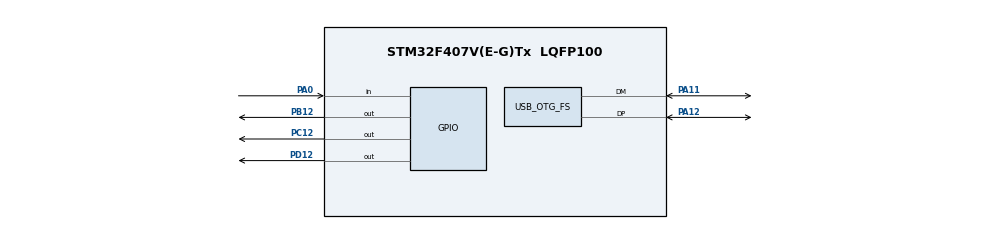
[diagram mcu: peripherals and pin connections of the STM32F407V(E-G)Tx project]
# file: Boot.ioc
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Mcu.Family=STM32F4
Mcu.Name=STM32F407V(E-G)Tx
Mcu.Package=LQFP100
NVIC.PriorityGroup=NVIC_PRIORITYGROUP_4
PA0-WKUP.Signal=GPIO_Input
PA11.Mode=Device_Only
PA11.Signal=USB_OTG_FS_DM
PA12.Mode=Device_Only
PA12.Signal=USB_OTG_FS_DP
PB12.Signal=GPIO_Output
PC12.Signal=GPIO_Output
PD12.Signal=GPIO_Output
PH0-OSC_IN.Mode=HSE-External-Oscillator
PH0-OSC_IN.Signal=RCC_OSC_IN
PH1-OSC_OUT.Mode=HSE-External-Oscillator
PH1-OSC_OUT.Signal=RCC_OSC_OUT
ProjectManager.HeapSize=0x200
ProjectManager.StackSize=0x400
ProjectManager.TargetToolchain=STM32CubeIDE
RCC.48MHZClocksFreq_Value=48000000
RCC.AHBFreq_Value=168000000
RCC.APB1CLKDivider=RCC_HCLK_DIV4
RCC.APB1Freq_Value=42000000
RCC.APB1TimFreq_Value=84000000
RCC.APB2CLKDivider=RCC_HCLK_DIV2
RCC.APB2Freq_Value=84000000
RCC.APB2TimFreq_Value=168000000
RCC.CortexFreq_Value=168000000
RCC.HCLKFreq_Value=168000000
RCC.HSE_VALUE=8000000
RCC.HSI_VALUE=16000000
RCC.LSE_VALUE=32768
RCC.PLLM=4
RCC.PLLN=168
RCC.PLLQ=7
RCC.SYSCLKFreq_VALUE=168000000
RCC.SYSCLKSource=RCC_SYSCLKSOURCE_PLLCLK
RCC.VCOOutputFreq_Value=336000000
USB_OTG_FS.Sof_enable=ENABLE
USB_OTG_FS.VirtualMode=Device_Only
board=custom

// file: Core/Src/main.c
/* USER CODE BEGIN Header */
/**
  ******************************************************************************
  * @file           : main.c
  * @brief          : Main program body
  ******************************************************************************
  * @attention
  *
  * Copyright (c) 2024 STMicroelectronics.
  * All rights reserved.
  *
  * This software is licensed under terms that can be found in the LICENSE file
  * in the root directory of this software component.
  * If no LICENSE file comes with this software, it is provided AS-IS.
  *
  ******************************************************************************
  */
/* USER CODE END Header */
#include "main.h"

/* USER CODE BEGIN Includes */
#include "app.h"
/* USER CODE END Includes */

PCD_HandleTypeDef hpcd_USB_OTG_FS;

void SystemClock_Config(void);
static void MX_GPIO_Init(void);

int main(void)
{

  /* MCU Configuration--------------------------------------------------------*/

  /* Reset of all peripherals, Initializes the Flash interface and the Systick. */
  HAL_Init();

  /* Configure the system clock */
  SystemClock_Config();

  /* Initialize all configured peripherals */
  MX_GPIO_Init();
  /* USER CODE BEGIN 2 */
  AppInit();
  /* USER CODE END 2 */

  /* Infinite loop */
  /* USER CODE BEGIN WHILE */
  while (1)
  {

	  AppTask();

    /* USER CODE END WHILE */

  }
}

void SystemClock_Config(void)
{
  LL_FLASH_SetLatency(LL_FLASH_LATENCY_5);
  while(LL_FLASH_GetLatency()!= LL_FLASH_LATENCY_5)
  {
  }
  LL_PWR_SetRegulVoltageScaling(LL_PWR_REGU_VOLTAGE_SCALE1);
  while (LL_PWR_IsActiveFlag_VOS() == 0)
  {
  }
  LL_RCC_HSE_Enable();

   /* Wait till HSE is ready */
  while(LL_RCC_HSE_IsReady() != 1)
  {

  }
  LL_RCC_PLL_ConfigDomain_SYS(LL_RCC_PLLSOURCE_HSE, LL_RCC_PLLM_DIV_4, 168, LL_RCC_PLLP_DIV_2);
  LL_RCC_PLL_ConfigDomain_48M(LL_RCC_PLLSOURCE_HSE, LL_RCC_PLLM_DIV_4, 168, LL_RCC_PLLQ_DIV_7);
  LL_RCC_PLL_Enable();

   /* Wait till PLL is ready */
  while(LL_RCC_PLL_IsReady() != 1)
  {

  }
  LL_RCC_SetAHBPrescaler(LL_RCC_SYSCLK_DIV_1);
  LL_RCC_SetAPB1Prescaler(LL_RCC_APB1_DIV_4);
  LL_RCC_SetAPB2Prescaler(LL_RCC_APB2_DIV_2);
  LL_RCC_SetSysClkSource(LL_RCC_SYS_CLKSOURCE_PLL);

   /* Wait till System clock is ready */
  while(LL_RCC_GetSysClkSource() != LL_RCC_SYS_CLKSOURCE_STATUS_PLL)
  {

  }
  LL_SetSystemCoreClock(168000000);

   /* Update the time base */
  if (HAL_InitTick (TICK_INT_PRIORITY) != HAL_OK)
  {
    Error_Handler();
  }
}

void MX_USB_OTG_FS_PCD_Init(void)
{

  hpcd_USB_OTG_FS.Instance = USB_OTG_FS;
  hpcd_USB_OTG_FS.Init.dev_endpoints = 4;
  hpcd_USB_OTG_FS.Init.speed = PCD_SPEED_FULL;
  hpcd_USB_OTG_FS.Init.dma_enable = DISABLE;
  hpcd_USB_OTG_FS.Init.phy_itface = PCD_PHY_EMBEDDED;
  hpcd_USB_OTG_FS.Init.Sof_enable = ENABLE;
  hpcd_USB_OTG_FS.Init.low_power_enable = DISABLE;
  hpcd_USB_OTG_FS.Init.lpm_enable = DISABLE;
  hpcd_USB_OTG_FS.Init.vbus_sensing_enable = DISABLE;
  hpcd_USB_OTG_FS.Init.use_dedicated_ep1 = DISABLE;
  if (HAL_PCD_Init(&hpcd_USB_OTG_FS) != HAL_OK)
  {
    Error_Handler();
  }

}

static void MX_GPIO_Init(void)
{
  LL_GPIO_InitTypeDef GPIO_InitStruct = {0};

  /* GPIO Ports Clock Enable */
  LL_AHB1_GRP1_EnableClock(LL_AHB1_GRP1_PERIPH_GPIOH);
  LL_AHB1_GRP1_EnableClock(LL_AHB1_GRP1_PERIPH_GPIOA);
  LL_AHB1_GRP1_EnableClock(LL_AHB1_GRP1_PERIPH_GPIOB);
  LL_AHB1_GRP1_EnableClock(LL_AHB1_GRP1_PERIPH_GPIOD);
  LL_AHB1_GRP1_EnableClock(LL_AHB1_GRP1_PERIPH_GPIOC);

  /**/
  LL_GPIO_ResetOutputPin(GPIOB, LL_GPIO_PIN_12);

  /**/
  LL_GPIO_ResetOutputPin(GPIOD, LL_GPIO_PIN_12);

  /**/
  LL_GPIO_ResetOutputPin(GPIOC, LL_GPIO_PIN_12);

  /**/
  GPIO_InitStruct.Pin = LL_GPIO_PIN_0;
  GPIO_InitStruct.Mode = LL_GPIO_MODE_INPUT;
  GPIO_InitStruct.Pull = LL_GPIO_PULL_NO;
  LL_GPIO_Init(GPIOA, &GPIO_InitStruct);

  /**/
  GPIO_InitStruct.Pin = LL_GPIO_PIN_12;
  GPIO_InitStruct.Mode = LL_GPIO_MODE_OUTPUT;
  GPIO_InitStruct.Speed = LL_GPIO_SPEED_FREQ_LOW;
  GPIO_InitStruct.OutputType = LL_GPIO_OUTPUT_PUSHPULL;
  GPIO_InitStruct.Pull = LL_GPIO_PULL_NO;
  LL_GPIO_Init(GPIOB, &GPIO_InitStruct);

  /**/
  GPIO_InitStruct.Pin = LL_GPIO_PIN_12;
  GPIO_InitStruct.Mode = LL_GPIO_MODE_OUTPUT;
  GPIO_InitStruct.Speed = LL_GPIO_SPEED_FREQ_LOW;
  GPIO_InitStruct.OutputType = LL_GPIO_OUTPUT_PUSHPULL;
  GPIO_InitStruct.Pull = LL_GPIO_PULL_NO;
  LL_GPIO_Init(GPIOD, &GPIO_InitStruct);

  /**/
  GPIO_InitStruct.Pin = LL_GPIO_PIN_12;
  GPIO_InitStruct.Mode = LL_GPIO_MODE_OUTPUT;
  GPIO_InitStruct.Speed = LL_GPIO_SPEED_FREQ_LOW;
  GPIO_InitStruct.OutputType = LL_GPIO_OUTPUT_PUSHPULL;
  GPIO_InitStruct.Pull = LL_GPIO_PULL_NO;
  LL_GPIO_Init(GPIOC, &GPIO_InitStruct);

}

void Error_Handler(void)
{
  __disable_irq();
  while (1)
  {
  }
}
